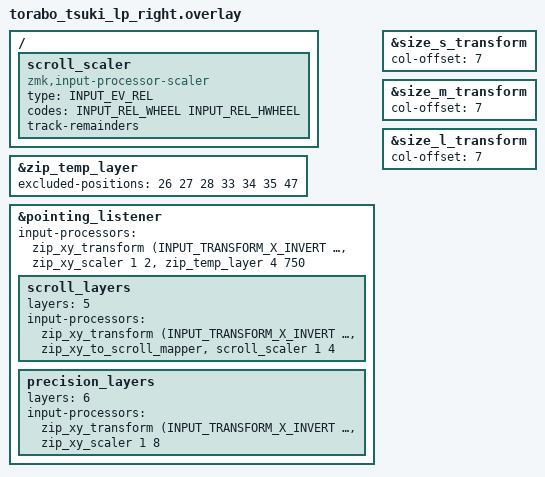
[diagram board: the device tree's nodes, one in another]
#include "torabo_tsuki_lp.dtsi"
#include <input/processors.dtsi>
#include <dt-bindings/zmk/input_transform.h>
#include <zephyr/dt-bindings/input/input-event-codes.h>

/ {
    scroll_scaler: scroll_scaler {
        compatible = "zmk,input-processor-scaler";
        #input-processor-cells = <2>;
        type = <INPUT_EV_REL>;
        codes = <INPUT_REL_WHEEL INPUT_REL_HWHEEL>;
        track-remainders;
    };
};

&zip_temp_layer {
    excluded-positions = <26 27 28 33 34 35 47>;
};

&pointing_listener {
    input-processors = <&zip_xy_transform (INPUT_TRANSFORM_X_INVERT | INPUT_TRANSFORM_Y_INVERT) &zip_xy_scaler 1 2 &zip_temp_layer 4 750>;

    scroll_layers: scroll_layers {
        layers = <5>;
        input-processors = <
            &zip_xy_transform (INPUT_TRANSFORM_X_INVERT | INPUT_TRANSFORM_Y_INVERT)
            &zip_xy_to_scroll_mapper
            &scroll_scaler 1 4
        >;
    };

    precision_layers: precision_layers {
        layers = <6>;
        input-processors = <
            &zip_xy_transform (INPUT_TRANSFORM_X_INVERT | INPUT_TRANSFORM_Y_INVERT)
            &zip_xy_scaler 1 8
        >;
    };
};

&size_s_transform {
    col-offset = <7>;
};

&size_m_transform {
    col-offset = <7>;
};

&size_l_transform {
    col-offset = <7>;
};
